# MIMXRT1011 register map
Vendor: nxp.com; File version: 1.0
CPU: CM7 r0p1, little endian, MPU, FPU, VTOR, 4 interrupt priority bits
Registers are 32-bit, read-write, reset 0x0 unless marked. A register's access mark holds for its fields unless they carry their own. Offsets are from the block's base; [hi:lo] are bit positions; {n}, {i} and the like mark numbered series; 'fields as' and 'values as' point back to an identical list.

## SNVS
Base 0x400D4000
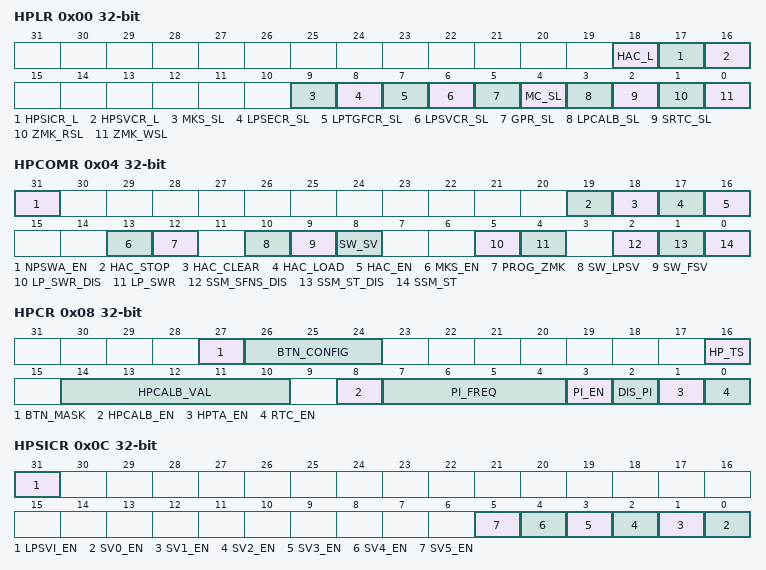
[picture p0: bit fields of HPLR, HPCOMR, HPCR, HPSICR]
0x00 HPLR — SNVS_HP Lock Register
  [18] HAC_L — High Assurance Counter Lock When set, prevents any writes to HPHACIVR, HPHACR, and HAC_EN bit of HPCOMR
    0=WRITE_ACCESS_ALLOWED (Write access is allowed); 1=WRITE_ACCESS_NOT_ALLOWED (Write access is not allowed)
  [17] HPSICR_L — HP Security Interrupt Control Register Lock When set, prevents any writes to the HPSICR
    values as HAC_L
  [16] HPSVCR_L — HP Security Violation Control Register Lock When set, prevents any writes to the HPSVCR
    values as HAC_L
  [9] MKS_SL — Master Key Select Soft Lock When set, prevents any writes to the MASTER_KEY_SEL field of the LPMKCR
    values as HAC_L
  [8] LPSECR_SL — LP Security Events Configuration Register Soft Lock When set, prevents any writes to the LPSECR
    values as HAC_L
  [7] LPTGFCR_SL — LP Tamper Glitch Filter Configuration Register Soft Lock When set, prevents any writes to the LPTGFCR
    values as HAC_L
  [6] LPSVCR_SL — LP Security Violation Control Register Soft Lock When set, prevents any writes to the LPSVCR
    values as HAC_L
  [5] GPR_SL — General Purpose Register Soft Lock When set, prevents any writes to the GPR
    0=WRITE_ALLOWED (Write access is allowed); 1=WRITE_NOT_ALLOWED (Write access is not allowed)
  [4] MC_SL — Monotonic Counter Soft Lock When set, prevents any writes (increments) to the MC Registers and MC_ENV bit
    0=WRITE_ALLOWED (Write access (increment) is allowed); 1=WRITE_NOT_ALLOWED (Write access (increment) is not allowed)
  [3] LPCALB_SL — LP Calibration Soft Lock When set, prevents any writes to the LP Calibration Value (LPCALB_VAL) and LP Calibration Enable (LPCALB_EN)
    values as GPR_SL
  [2] SRTC_SL — Secure Real Time Counter Soft Lock When set, prevents any writes to the SRTC Registers, SRTC_ENV, and SRTC_INV_EN bits
    values as GPR_SL
  [1] ZMK_RSL — Zeroizable Master Key Read Soft Lock When set, prevents any software reads to the ZMK Registers and ZMK_ECC_VALUE field of the LPMKCR
    0=READ_ALLOWED (Read access is allowed (only in software Programming mode)); 1=READ_NOT_ALLOWED (Read access is not allowed)
  [0] ZMK_WSL — Zeroizable Master Key Write Soft Lock When set, prevents any writes (software and hardware) to the ZMK registers and the ZMK_HWP, ZMK_VAL, and ZMK_ECC_EN fields of the LPMKCR
    values as GPR_SL
0x04 HPCOMR — SNVS_HP Command Register
  [31] NPSWA_EN — Non-Privileged Software Access Enable When set, allows non-privileged software to access all SNVS registers, including those that are privileged software read/write access only
  [19] HAC_STOP — High Assurance Counter Stop This bit can be set only when SSM is in soft fail state
  [18] HAC_CLEAR wo — High Assurance Counter Clear When set, it clears the High Assurance Counter Register
    0=NO_ACTION; 1=CLEAR_HAC (Clear the HAC)
  [17] HAC_LOAD wo — High Assurance Counter Load When set, it loads the High Assurance Counter Register with the value of the High Assurance Counter Load Register
    0=NO_ACTION; 1=LOAD_HAC (Load the HAC)
  [16] HAC_EN — High Assurance Counter Enable This bit controls the SSM transition from the soft fail to the hard fail state
    0=DISABLED (High Assurance Counter is disabled); 1=ENABLED (High Assurance Counter is enabled)
  [13] MKS_EN — Master Key Select Enable When not set, the one time programmable (OTP) master key is selected by default
    0=SELECT_OTP (OTP master key is selected as an SNVS master key); 1=SELECT_PER_LPMKCR (SNVS master key is selected according to the setting of the MASTER_KEY_SEL field of LPMKCR)
  [12] PROG_ZMK wo — Program Zeroizable Master Key This bit activates ZMK hardware programming mechanism
    0=NO_ACTION; 1=PROGRAM_KEY (Activate hardware key programming mechanism)
  [10] SW_LPSV — LP Software Security Violation When set, SNVS_LP treats this bit as a security violation
  [9] SW_FSV — Software Fatal Security Violation When set, the system security monitor treats this bit as a fatal security violation
  [8] SW_SV — Software Security Violation When set, the system security monitor treats this bit as a non-fatal security violation
  [5] LP_SWR_DIS — LP Software Reset Disable When set, disables the LP software reset
    0=ENABLED (LP software reset is enabled); 1=DISABLED (LP software reset is disabled)
  [4] LP_SWR wo — LP Software Reset When set to 1, most registers in the SNVS_LP section are reset, but the following registers are not reset by an LP software reset: Monotonic Counter Secure Real Time Counter Time Alarm Register This bit cannot be set when the LP_SWR_DIS bit is set
    0=NO_ACTION; 1=RESET (Reset LP section)
  [2] SSM_SFNS_DIS — SSM Soft Fail to Non-Secure State Transition Disable When set, it disables the SSM transition from soft fail to non-secure state
    0=ENABLED (Soft Fail to Non-Secure State transition is enabled); 1=DISABLED (Soft Fail to Non-Secure State transition is disabled)
  [1] SSM_ST_DIS — SSM Secure to Trusted State Transition Disable When set, disables the SSM transition from secure to trusted state
    0=ENABLED (Secure to Trusted State transition is enabled); 1=DISABLED (Secure to Trusted State transition is disabled)
  [0] SSM_ST wo — SSM State Transition Transition state of the system security monitor
0x08 HPCR — SNVS_HP Control Register
  [27] BTN_MASK — Button interrupt mask
  [26:24] BTN_CONFIG — Button Configuration
  [16] HP_TS — HP Time Synchronize
    0=NO_ACTION; 1=SYNC_TIME (Synchronize the HP Time Counter to the LP Time Counter)
  [14:10] HPCALB_VAL — HP Calibration Value Defines signed calibration value for the HP Real Time Counter
    0=ADD_0_PER_32768_TICKS (+0 counts per each 32768 ticks of the counter); 1=ADD_1_PER_32768_TICKS (+1 counts per each 32768 ticks of the counter); 2=ADD_2_PER_32768_TICKS (+2 counts per each 32768 ticks of the counter); 15=ADD_15_PER_32768_TICKS (+15 counts per each 32768 ticks of the counter); 16=SUB_16_PER_32768_TICKS (-16 counts per each 32768 ticks of the counter); 17=SUB_15_PER_32768_TICKS (-15 counts per each 32768 ticks of the counter); 30=SUB_2_PER_32768_TICKS (-2 counts per each 32768 ticks of the counter); 31=SUB_1_PER_32768_TICKS (-1 counts per each 32768 ticks of the counter)
  [8] HPCALB_EN — HP Real Time Counter Calibration Enabled Indicates that the time calibration mechanism is enabled.
    0=DISABLED (HP Timer calibration disabled); 1=ENABLED (HP Timer calibration enabled)
  [7:4] PI_FREQ — Periodic Interrupt Frequency Defines frequency of the periodic interrupt
    {v}=USE_BIT_{v} (- bit {v} of the HPRTCLR is selected as a source of the periodic interrupt) (v=0..14); 15=USE_BIT_1r5 (- bit 15 of the HPRTCLR is selected as a source of the periodic interrupt)
  [3] PI_EN — HP Periodic Interrupt Enable The periodic interrupt can be generated only if the HP Real Time Counter is enabled
    0=DISABLED (HP Periodic Interrupt is disabled); 1=ENABLED (HP Periodic Interrupt is enabled)
  [2] DIS_PI — Disable periodic interrupt in the functional interrupt
    0=ENABLED (Periodic interrupt will trigger a functional interrupt); 1=DISABLED (Disable periodic interrupt in the function interrupt)
  [1] HPTA_EN — HP Time Alarm Enable When set, the time alarm interrupt is generated if the value in the HP Time Alarm Registers is equal to the value of the HP Real Time Counter
    0=DISABLED (HP Time Alarm Interrupt is disabled); 1=ENABLED (HP Time Alarm Interrupt is enabled)
  [0] RTC_EN — HP Real Time Counter Enable
    0=DISABLED (RTC is disabled); 1=ENABLED (RTC is enabled)
0x0C HPSICR — SNVS_HP Security Interrupt Control Register
  [31] LPSVI_EN — LP Security Violation Interrupt Enable This bit enables generating of the security interrupt to the host processor upon security violation signal from the LP section
    0=DISABLED (LP Security Violation Interrupt is Disabled); 1=ENABLED (LP Security Violation Interrupt is Enabled)
  [n] SV{n}_EN (n=0..5) — Security Violation {n} Interrupt Enable Setting this bit to 1 enables generation of the security interrupt to the host processor upon detection of the Security Violation {n} security violation
    0=DISABLED (Security Violation {n} Interrupt is Disabled); 1=ENABLED (Security Violation {n} Interrupt is Enabled)
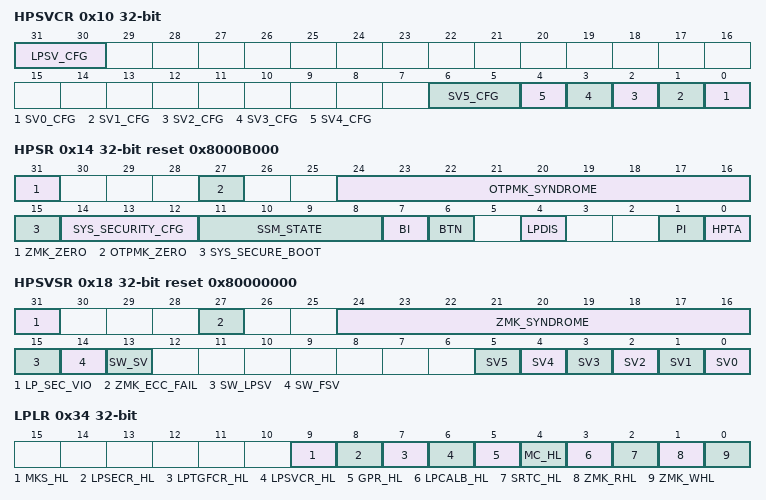
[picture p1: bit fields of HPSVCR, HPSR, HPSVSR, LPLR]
0x10 HPSVCR — SNVS_HP Security Violation Control Register
  [31:30] LPSV_CFG — LP Security Violation Configuration This field configures the LP security violation source.
    0=DISABLED (LP security violation is disabled); 1=NON_FATAL (LP security violation is a non-fatal violation); 0b1x=FATAL (LP security violation is a fatal violation)
  [6:5] SV5_CFG — Security Violation 5 Security Violation Configuration This field configures the Security Violation 5 Security Violation Input
    0=DISABLED (Security Violation 5 is disabled); 1=NON_FATAL (Security Violation 5 is a non-fatal violation); 0b1x=FATAL (Security Violation 5 is a fatal violation)
  [n] SV{n}_CFG (n=0..4) — Security Violation {n} Security Violation Configuration This field configures the Security Violation {n} Security Violation Input
    0=NON_FATAL (Security Violation {n} is a non-fatal violation); 1=FATAL (Security Violation {n} is a fatal violation)
0x14 HPSR reset 0x8000B000 — SNVS_HP Status Register
  [31] ZMK_ZERO ro — Zeroizable Master Key is Equal to Zero
    0=ZMK_NOT_ZERO (The ZMK is not zero.); 1=ZMK_IS_ZERO (The ZMK is zero.)
  [27] OTPMK_ZERO ro — One Time Programmable Master Key is Equal to Zero
    0=OTPMK_NOT_ZERO (The OTPMK is not zero.); 1=OTPMK_IS_ZERO (The OTPMK is zero.)
  [24:16] OTPMK_SYNDROME ro — One Time Programmable Master Key Syndrome In the case of a single-bit error, the eight lower bits of this value indicate the bit number of error location
  [15] SYS_SECURE_BOOT ro — System Secure Boot If SYS_SECURE_BOOT is 1, the chip boots from internal ROM
  [14:12] SYS_SECURITY_CFG ro — System Security Configuration This field reflects the three security configuration inputs to SNVS
    0=FAB_CONFIG (Fab Configuration - the default configuration of newly fabricated chips); 1=OPEN_CONFIG (Open Configuration - the configuration after NXP-programmable fuses have been blown); 3=CLOSED_CONFIG (Closed Configuration - the configuration after OEM-programmable fuses have been blown); 7=FIELD_RETURN_CONFIG (Field Return Configuration - the configuration of chips that are returned to NXP for analysis)
  [11:8] SSM_STATE ro — System Security Monitor State This field contains the encoded state of the SSM's state machine
    0=INIT; 1=HARD_FAIL; 3=SOFT_FAIL; 8=INTERMEDIATE (Init Intermediate (transition state between Init and Check - SSM stays in this state only one clock cycle)); 9=CHECK; 11=NON_SECURE; 13=TRUSTED; 15=SECURE
  [7] BI write-1-clears — Button Interrupt Signal ipi_snvs_btn_int_b was asserted.
  [6] BTN ro — Button Value of the BTN input
  [4] LPDIS ro — Low Power Disable If 1, the low power section has been disabled by means of an input signal to SNVS
  [1] PI write-1-clears — Periodic Interrupt Indicates that periodic interrupt has occurred since this bit was last cleared.
    0=NOREPORT (No periodic interrupt occurred.); 1=REPORTED (A periodic interrupt occurred.)
  [0] HPTA write-1-clears — HP Time Alarm Indicates that the HP Time Alarm has occurred since this bit was last cleared.
    0=NOREPORT (No time alarm interrupt occurred.); 1=REPORTED (A time alarm interrupt occurred.)
0x18 HPSVSR reset 0x80000000 — SNVS_HP Security Violation Status Register
  [31] LP_SEC_VIO ro — LP Security Violation A security volation was detected in the SNVS low power section
  [27] ZMK_ECC_FAIL write-1-clears — Zeroizable Master Key Error Correcting Code Check Failure When set, this bit triggers a bad key violation to the SSM and a security violation to the SNVS_LP section, which clears security sensitive data
    0=NOREPORT (ZMK ECC Failure was not detected.); 1=REPORTED (ZMK ECC Failure was detected.)
  [24:16] ZMK_SYNDROME ro — Zeroizable Master Key Syndrome The ZMK syndrome indicates the single-bit error location and parity for the ZMK register
  [15] SW_LPSV ro — LP Software Security Violation This bit is a read-only copy of the SW_LPSV bit in the HP Command Register
  [14] SW_FSV ro — Software Fatal Security Violation This bit is a read-only copy of the SW_FSV bit in the HP Command Register
  [13] SW_SV ro — Software Security Violation This bit is a read-only copy of the SW_SV bit in the HP Command Register
  [n] SV{n} write-1-clears (n=0..5) — Security Violation {n} security violation was detected.
    0=NOREPORT (No Security Violation {n} security violation was detected.); 1=REPORTED (Security Violation {n} security violation was detected.)
0x1C HPHACIVR — SNVS_HP High Assurance Counter IV Register
  [31:0] HAC_COUNTER_IV — High Assurance Counter Initial Value This register is used to set the starting count value to the high assurance counter
0x20 HPHACR ro — SNVS_HP High Assurance Counter Register
  [31:0] HAC_COUNTER — High Assurance Counter When the HAC_EN bit is set and the SSM is in the soft fail state, this counter starts to count down with the system clock
0x24 HPRTCMR — SNVS_HP Real Time Counter MSB Register
  [14:0] RTC — HP Real Time Counter The most-significant 15 bits of the RTC
0x28 HPRTCLR — SNVS_HP Real Time Counter LSB Register
  [31:0] RTC — HP Real Time Counter least-significant 32 bits
0x2C HPTAMR — SNVS_HP Time Alarm MSB Register
  [14:0] HPTA_MS — HP Time Alarm, most-significant 15 bits
0x30 HPTALR — SNVS_HP Time Alarm LSB Register
  [31:0] HPTA_LS — HP Time Alarm, 32 least-significant bits
0x34 LPLR — SNVS_LP Lock Register
  [9] MKS_HL — Master Key Select Hard Lock When set, prevents any writes to the MASTER_KEY_SEL field of the LP Master Key Control Register
    0=WRITE_ACCESS_ALLOWED (Write access is allowed.); 1=WRITE_ACCESS_NOT_ALLOWED (Write access is not allowed.)
  [8] LPSECR_HL — LP Security Events Configuration Register Hard Lock When set, prevents any writes to the LPSECR
    values as MKS_HL
  [7] LPTGFCR_HL — LP Tamper Glitch Filter Configuration Register Hard Lock When set, prevents any writes to the LPTGFCR
    values as MKS_HL
  [6] LPSVCR_HL — LP Security Violation Control Register Hard Lock When set, prevents any writes to the LPSVCR
    values as MKS_HL
  [5] GPR_HL — General Purpose Register Hard Lock When set, prevents any writes to the GPR
    values as MKS_HL
  [4] MC_HL — Monotonic Counter Hard Lock When set, prevents any writes (increments) to the MC Registers and MC_ENV bit
    0=WRITE_ACCESS_ALLOWED (Write access (increment) is allowed.); 1=WRITE_ACCESS_NOT_ALLOWED (Write access (increment) is not allowed.)
  [3] LPCALB_HL — LP Calibration Hard Lock When set, prevents any writes to the LP Calibration Value (LPCALB_VAL) and LP Calibration Enable (LPCALB_EN)
    values as MKS_HL
  [2] SRTC_HL — Secure Real Time Counter Hard Lock When set, prevents any writes to the SRTC registers, SRTC_ENV, and SRTC_INV_EN bits
    values as MKS_HL
  [1] ZMK_RHL — Zeroizable Master Key Read Hard Lock When set, prevents any software reads to the ZMK registers and ZMK_ECC_VALUE field of the LPMKCR
    0=READ_ACCESS_ALLOWED (Read access is allowed (only in software programming mode).); 1=READ_ACCESS_NOT_ALLOWED (Read access is not allowed.)
  [0] ZMK_WHL — Zeroizable Master Key Write Hard Lock When set, prevents any writes (software and hardware) to the ZMK registers and ZMK_HWP, ZMK_VAL, and ZMK_ECC_EN fields of the LPMKCR
    values as MKS_HL
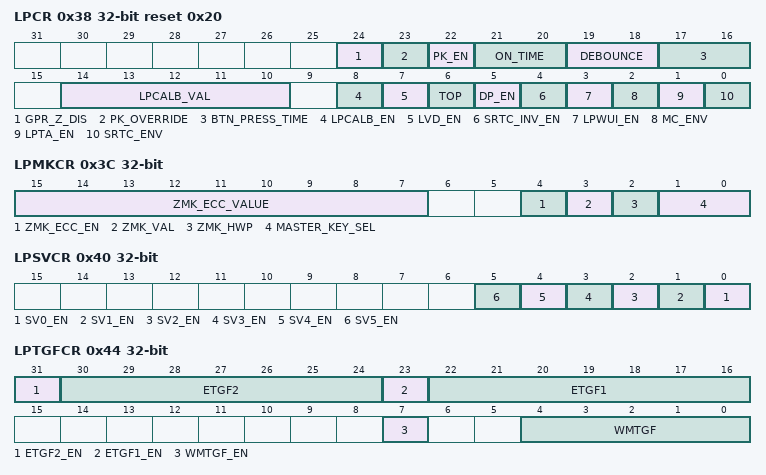
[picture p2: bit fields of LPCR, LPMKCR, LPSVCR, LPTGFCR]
0x38 LPCR reset 0x20 — SNVS_LP Control Register
  [24] GPR_Z_DIS — General Purpose Registers Zeroization Disable
  [23] PK_OVERRIDE — PMIC On Request Override The value written to PK_OVERRIDE will be asserted on output signal snvs_lp_pk_override
  [22] PK_EN — PMIC On Request Enable The value written to PK_EN will be asserted on output signal snvs_lp_pk_en
  [21:20] ON_TIME — The ON_TIME field is used to configure the period of time after BTN is asserted before pmic_en_b is asserted to turn on the SoC power
  [19:18] DEBOUNCE — This field configures the amount of debounce time for the BTN input signal
  [17:16] BTN_PRESS_TIME — This field configures the button press time out values for the PMIC Logic
  [14:10] LPCALB_VAL — LP Calibration Value Defines signed calibration value for SRTC
    0=ADD_0_PER_32768_TICKS (+0 counts per each 32768 ticks of the counter clock); 1=ADD_1_PER_32768_TICKS (+1 counts per each 32768 ticks of the counter clock); 2=ADD_2_PER_32768_TICKS (+2 counts per each 32768 ticks of the counter clock); 15=ADD_15_PER_32768_TICKS (+15 counts per each 32768 ticks of the counter clock); 16=SUB_16_PER_32768_TICKS (-16 counts per each 32768 ticks of the counter clock); 17=SUB_15_PER_32768_TICKS (-15 counts per each 32768 ticks of the counter clock); 30=SUB_2_PER_32768_TICKS (-2 counts per each 32768 ticks of the counter clock); 31=SUB_1_PER_32768_TICKS (-1 counts per each 32768 ticks of the counter clock)
  [8] LPCALB_EN — LP Calibration Enable When set, enables the SRTC calibration mechanism
    0=DISABLED (SRTC Time calibration is disabled.); 1=ENABLED (SRTC Time calibration is enabled.)
  [7] LVD_EN — Digital Low-Voltage Event Enable By default the detection of a low-voltage event does not cause the pmic_en_b signal to be asserted
  [6] TOP — Turn off System Power Asserting this bit causes a signal to be sent to the Power Management IC to turn off the system power
    0=KEEP_ON (Leave system power on.); 1=TURN_OFF (Turn off system power.)
  [5] DP_EN — Dumb PMIC Enabled When set, software can control the system power
    0=SMART_PMIC_ENABLED; 1=DUMB_PMIC_ENABLED
  [4] SRTC_INV_EN — If this bit is 1, in the case of a security violation the SRTC stops counting and the SRTC is invalidated (SRTC_ENV bit is cleared)
    0=KEEP_VALID (SRTC stays valid in the case of security violation (other than a software violation (HPSVSR[SW_LPSV] = 1 or HPCOMR[SW_LPSV] = 1)).); 1=INVALIDATE (SRTC is invalidated in the case of security violation.)
  [3] LPWUI_EN — LP Wake-Up Interrupt Enable This interrupt line should be connected to the external pin and is intended to inform the external chip about an SNVS_LP event (tamper event, MC rollover, SRTC rollover, or time alarm )
  [2] MC_ENV — Monotonic Counter Enabled and Valid When set, the MC can be incremented (by write transaction to the LPSMCMR or LPSMCLR)
    0=DISABLED (MC is disabled or invalid.); 1=ENABLED (MC is enabled and valid.)
  [1] LPTA_EN — LP Time Alarm Enable When set, the SNVS functional interrupt is asserted if the LP Time Alarm Register is equal to the 32 MSBs of the secure real time counter
    0=DISABLED (LP time alarm interrupt is disabled.); 1=ENABLED (LP time alarm interrupt is enabled.)
  [0] SRTC_ENV — Secure Real Time Counter Enabled and Valid When set, the SRTC becomes operational
    0=DISABLED (SRTC is disabled or invalid.); 1=ENABLED (SRTC is enabled and valid.)
0x3C LPMKCR — SNVS_LP Master Key Control Register
  [15:7] ZMK_ECC_VALUE ro — Zeroizable Master Key Error Correcting Code Value This field is automatically calculated and set when one is written into ZMK_ECC_EN bit of this register
  [4] ZMK_ECC_EN — Zeroizable Master Key Error Correcting Code Check Enable Writing one to this field automatically calculates and sets the ZMK ECC value in the ZMK_ECC_VALUE field of this register
    0=DISABLED (ZMK ECC check is disabled.); 1=ENABLED (ZMK ECC check is enabled.)
  [3] ZMK_VAL — Zeroizable Master Key Valid When set, the ZMK value can be selected by the master key control block for use by cryptographic modules
    0=INVALID (ZMK is not valid.); 1=VALID (ZMK is valid.)
  [2] ZMK_HWP — Zeroizable Master Key hardware Programming mode When set, only the hardware key programming mechanism can set the ZMK and software cannot read it
    0=SW_PROG_MODE (ZMK is in the software programming mode.); 1=HW_PROG_MODE (ZMK is in the hardware programming mode.)
  [1:0] MASTER_KEY_SEL — Master Key Select These bits select the SNVS Master Key output when Master Key Select bits are enabled by MKS_EN bit in the HPCOMR
    0b0x=SELECT_OTPMK (Select one time programmable master key.); 2=SELECT_ZMK (Select zeroizable master key when MKS_EN bit is set .); 3=SELECT_COMBO (Select combined master key when MKS_EN bit is set .)
0x40 LPSVCR — SNVS_LP Security Violation Control Register
  [n] SV{n}_EN (n=0..5) — Security Violation {n} Enable This bit enables Security Violation {n} Input
    0=DISABLED (Security Violation {n} is disabled in the LP domain.); 1=ENABLED (Security Violation {n} is enabled in the LP domain.)
0x44 LPTGFCR — SNVS_LP Tamper Glitch Filters Configuration Register
  [31] ETGF2_EN — External Tamper Glitch Filter 2 Enable When set, enables the external tamper glitch filter 2.
    0=BYPASSED (External tamper glitch filter 2 is bypassed.); 1=ENABLED (External tamper glitch filter 2 is enabled.)
  [30:24] ETGF2 — External Tamper Glitch Filter 2 Configures the length of the digital glitch filter for the external tamper 2 pin between 128 and 32640 SRTC clock cycles
  [23] ETGF1_EN — External Tamper Glitch Filter 1 Enable When set, enables the external tamper glitch filter 1.
    0=BYPASSED (External tamper glitch filter 1 is bypassed.); 1=ENABLED (External tamper glitch filter 1 is enabled.)
  [22:16] ETGF1 — External Tamper Glitch Filter 1 Configures the length of the digital glitch filter for the external tamper 1 pin between 128 and 32640 SRTC clock cycles
  [7] WMTGF_EN — Wire-Mesh Tamper Glitch Filter Enable When set, enables the wire-mesh tamper glitch filter
    0=BYPASSED (Wire-mesh tamper glitch filter is bypassed.); 1=ENABLED (Wire-mesh tamper glitch filter is enabled.)
  [4:0] WMTGF — Wire-Mesh Tamper Glitch Filter Configures the length of the digital glitch filter for the wire-mesh tamper 1 and 2 pins between 1 and 63 SRTC clock cycles
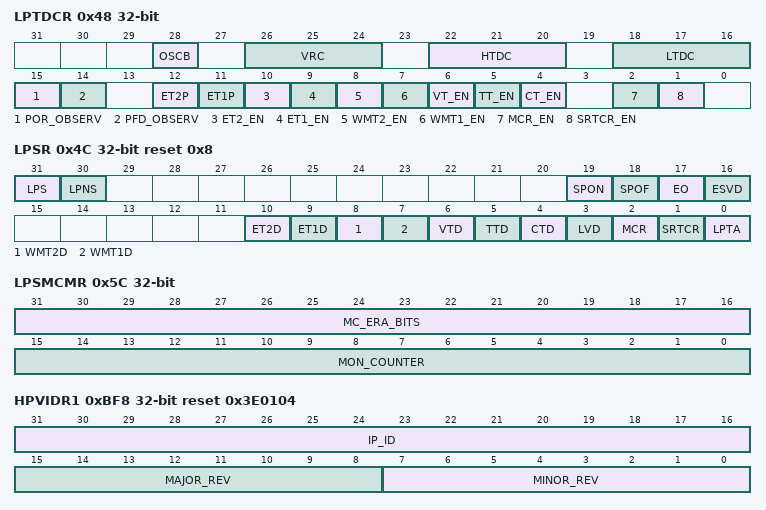
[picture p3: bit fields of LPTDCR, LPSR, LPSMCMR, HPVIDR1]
0x48 LPTDCR — SNVS_LP Tamper Detect Configuration Register
  [28] OSCB — Oscillator Bypass When OSCB=1 the osc_bypass signal is asserted
    0=NOT_BYPASSED (Normal SRTC clock oscillator not bypassed.); 1=BYPASSED (Normal SRTC clock oscillator bypassed. Alternate clock can drive the SRTC clock source.)
  [26:24] VRC — Voltage Reference Configuration These configuration bits are wired as an output of the module.
  [22:20] HTDC — High Temperature Detect Configuration These configuration bits are wired as an output of the module
  [18:16] LTDC — Low Temp Detect Configuration These configuration bits are wired as an output of the module.
  [15] POR_OBSERV — Power On Reset (POR) Observability Flop The asynchronous reset input of this flop is connected directly to the output of the POR analog circuitry (external to the SNVS
  [14] PFD_OBSERV — System Power Fail Detector (PFD) Observability Flop The asynchronous reset input of this flop is connected directly to the inverted output of the PFD analog circuitry (external to the SNVS block)
  [12] ET2P — External Tampering 2 Polarity This bit is used to determine the polarity of external tamper 2.
    0=ACTIVE_LOW (External tamper 2 is active low.); 1=ACTIVE_HIGH (External tamper 2 is active high.)
  [11] ET1P — External Tampering 1 Polarity This bit is used to determine the polarity of external tamper 1.
    0=ACTIVE_LOW (External tamper 1 is active low.); 1=ACTIVE_HIGH (External tamper 1 is active high.)
  [10] ET2_EN — External Tampering 2 Enable When set, external tampering 2 detection generates an LP security violation
    0=DISABLED (External tamper 2 is disabled.); 1=ENABLED (External tamper 2 is enabled.)
  [9] ET1_EN — External Tampering 1 Enable When set, external tampering 1 detection generates an LP security violation
    0=DISABLED (External tamper 1 is disabled.); 1=ENABLED (External tamper 1 is enabled.)
  [8] WMT2_EN — Wire-Mesh Tampering 2 Enable When set, wire-mesh tampering 2 detection generates an LP security violation
    0=DISABLED (Wire-mesh tamper 2 is disabled.); 1=ENABLED (Wire-mesh tamper 2 is enabled.)
  [7] WMT1_EN — Wire-Mesh Tampering 1 Enable When set, wire-mesh tampering 1 detection generates an LP security violation
    0=DISABLED (Wire-mesh tamper 1 is disabled.); 1=ENABLED (Wire-mesh tamper 1 is enabled.)
  [6] VT_EN — Voltage Tamper Enable Voltage Tamper Enable should be enabled 500 us after setting SCSC_SOSC_CTR [VOLT_TEMP_TAMPER_EN]
    0=DISABLED (Voltage tamper is disabled.); 1=ENABLED (Voltage tamper is enabled.)
  [5] TT_EN — Temperature Tamper Enable When set, a temperature monitor tamper generates an LP security violation
    0=DISABLED (Temperature tamper is disabled.); 1=ENABLED (Temperature tamper is enabled.)
  [4] CT_EN — Clock Tamper Enable When set, a clock monitor tamper generates an LP security violation.
    0=DISABLED (Clock tamper is disabled.); 1=ENABLED (Clock tamper is enabled.)
  [2] MCR_EN — MC Rollover Enable When set, an MC Rollover event generates an LP security violation.
    0=DISABLED (MC rollover is disabled.); 1=ENABLED (MC rollover is enabled.)
  [1] SRTCR_EN — SRTC Rollover Enable When set, an SRTC rollover event generates an LP security violation.
    0=DISABLED (SRTC rollover is disabled.); 1=ENABLED (SRTC rollover is enabled.)
0x4C LPSR reset 0x8 — SNVS_LP Status Register
  [31] LPS ro — LP Section is Secured Indicates that the LP section is provisioned/programmed in the secure or trusted state
    0=NOT_PRGRMD_IN_SECURE_OR_TRUSTED_STATE (LP section was not programmed in secure or trusted state.); 1=WAS_PRGRMD_IN_SECURE_OR_TRUSTED_STATE (LP section was programmed in secure or trusted state.)
  [30] LPNS ro — LP Section is Non-Secured Indicates that LP section was provisioned/programmed in the non-secure state
    0=NOT_PRGRMD_IN_NON_SECURE_STATE (LP section was not programmed in the non-secure state.); 1=WAS_PRGRMD_IN_NON_SECURE_STATE (LP section was programmed in the non-secure state.)
  [19] SPON write-1-clears — Set Power On The SPON bit is set when the set_pwr_on_irq interrupt is triggered, which happens when the power button is pressed longer than the configured debounce time
    0=NOREPORT (Set Power On Interrupt was not detected.); 1=REPORTED (Set Power On Interrupt was detected.)
  [18] SPOF write-1-clears — Set Power Off The SPO bit is set when the power button is pressed longer than the configured debounce time
    0=NOREPORT (Set Power Off was not detected.); 1=REPORTED (Set Power Off was detected.)
  [17] EO write-1-clears — Emergency Off This bit is set when a power off is requested.
    0=NOREPORT (Emergency off was not detected.); 1=REPORTED (Emergency off was detected.)
  [16] ESVD write-1-clears — External Security Violation Detected Indicates that a security violation is detected on one of the HP security violation ports
    0=NOREPORT (No external security violation.); 1=REPORTED (External security violation is detected.)
  [10] ET2D write-1-clears — External Tampering 2 Detected
    0=NOREPORT (External tampering 2 not detected.); 1=REPORTED (External tampering 2 detected.)
  [9] ET1D write-1-clears — External Tampering 1 Detected
    0=NOREPORT (External tampering 1 not detected.); 1=REPORTED (External tampering 1 detected.)
  [8] WMT2D write-1-clears — Wire-Mesh Tampering 2 Detected
    0=NOREPORT (Wire-mesh tampering 2 not detected.); 1=REPORTED (Wire-mesh tampering 2 detected.)
  [7] WMT1D write-1-clears — Wire-Mesh Tampering 1 Detected
    0=NOREPORT (Wire-mesh tampering 1 not detected.); 1=REPORTED (Wire-mesh tampering 1 detected.)
  [6] VTD write-1-clears — Voltage Tampering Detected
    0=NOREPORT (Voltage tampering not detected.); 1=REPORTED (Voltage tampering detected.)
  [5] TTD write-1-clears — Temperature Tamper Detected
    0=NOREPORT (No temperature tamper.); 1=REPORTED (Temperature tamper is detected.)
  [4] CTD write-1-clears — Clock Tampering Detected
    0=NOREPORT (No clock tamper.); 1=REPORTED (Clock tamper is detected.)
  [3] LVD write-1-clears — Digital Low Voltage Event Detected
    0=NOLOWVOLT (No low voltage event detected.); 1=LOWVOLTDETECTED (Low voltage event is detected.)
  [2] MCR write-1-clears — Monotonic Counter Rollover
    0=NOREPORT (MC has not reached its maximum value.); 1=REPORTED (MC has reached its maximum value.)
  [1] SRTCR write-1-clears — Secure Real Time Counter Rollover
    0=NOREPORT (SRTC has not reached its maximum value.); 1=REPORTED (SRTC has reached its maximum value.)
  [0] LPTA write-1-clears — LP Time Alarm
    values as HPSR.HPTA
0x50 LPSRTCMR — SNVS_LP Secure Real Time Counter MSB Register
  [14:0] SRTC — LP Secure Real Time Counter The most-significant 15 bits of the SRTC
0x54 LPSRTCLR — SNVS_LP Secure Real Time Counter LSB Register
  [31:0] SRTC — LP Secure Real Time Counter least-significant 32 bits This register can be programmed only when SRTC is not active and not locked, meaning the SRTC_ENV, SRTC_SL, and SRTC_HL bits are not set
0x58 LPTAR — SNVS_LP Time Alarm Register
  [31:0] LPTA — LP Time Alarm This register can be programmed only when the LP time alarm is disabled (LPTA_EN bit is not set)
0x5C LPSMCMR — SNVS_LP Secure Monotonic Counter MSB Register
  [31:16] MC_ERA_BITS ro — Monotonic Counter Era Bits These bits are inputs to the module and typically connect to fuses
  [15:0] MON_COUNTER — Monotonic Counter most-significant 16 Bits Note that writing to this register does not change the value of this field to the value that was written
0x60 LPSMCLR — SNVS_LP Secure Monotonic Counter LSB Register
  [31:0] MON_COUNTER — Monotonic Counter bits Note that writing to this register does not change the value of this field to the value that was written
0x64 LPLVDR — SNVS_LP Digital Low-Voltage Detector Register
  [31:0] LVD — Low-Voltage Detector Value
0x68 LPGPR0_legacy_alias — SNVS_LP General Purpose Register 0 (legacy alias)
  [31:0] GPR — General Purpose Register When GPR_SL or GPR_HL bit is set, the register cannot be programmed.
{0x6C+4i} LPZMKR[{i}] (i=0..7) — SNVS_LP Zeroizable Master Key Register
  [31:0] ZMK — Zeroizable Master Key Each of these registers contains 32 bits of the 256-bit ZMK value
{0x90+4i} LPGPR_alias[{i}] (i=0..3) — SNVS_LP General Purpose Registers 0 .. 3
  fields as LPGPR0_legacy_alias
{0x100+4i} LPGPR[{i}] (i=0..3) — SNVS_LP General Purpose Registers 0 .. 3
  fields as LPGPR0_legacy_alias
0xBF8 HPVIDR1 ro reset 0x3E0104 — SNVS_HP Version ID Register 1
  [31:16] IP_ID — SNVS block ID
  [15:8] MAJOR_REV — SNVS block major version number
  [7:0] MINOR_REV — SNVS block minor version number
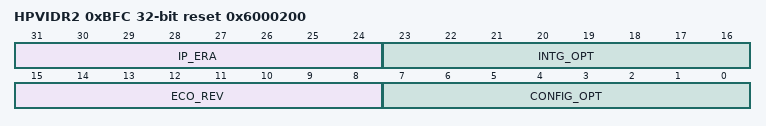
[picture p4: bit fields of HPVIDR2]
0xBFC HPVIDR2 ro reset 0x6000200 — SNVS_HP Version ID Register 2
  [31:24] IP_ERA — IP Era 00h - Era 1 or 2 03h - Era 3 04h - Era 4 05h - Era 5 06h - Era 6
  [23:16] INTG_OPT — SNVS Integration Options
  [15:8] ECO_REV — SNVS ECO Revision
  [7:0] CONFIG_OPT — SNVS Configuration Options
